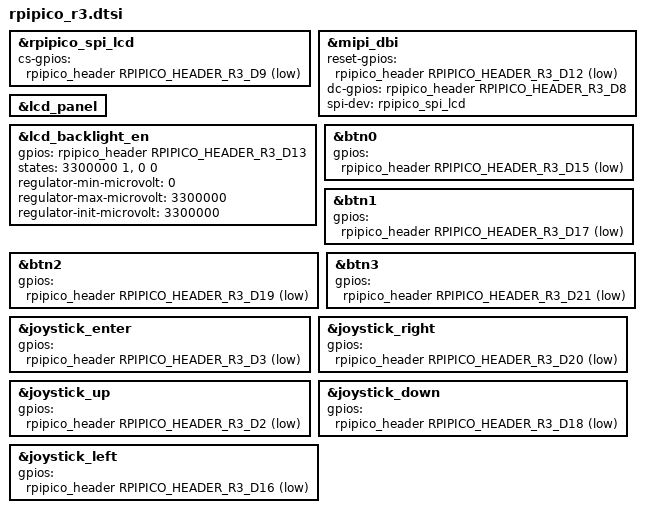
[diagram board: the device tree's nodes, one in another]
/*
 * SPDX-FileCopyrightText: Copyright (c) 2024-2026 TiaC Systems
 * SPDX-License-Identifier: Apache-2.0
 */

#include "rpipico_r3-connect.dtsi"

#include "st7789v_240x240ls.dtsi"

#include <zephyr/dt-bindings/gpio/gpio.h>

#include <zephyr/dt-bindings/gpio/raspberrypi-pico-header-r3.h>

&rpipico_spi_lcd {
	status = "okay";
	cs-gpios = <&rpipico_header RPIPICO_HEADER_R3_D9 GPIO_ACTIVE_LOW>;	/* GP9 */
};

&mipi_dbi {
	status = "okay";
	reset-gpios = <&rpipico_header RPIPICO_HEADER_R3_D12 GPIO_ACTIVE_LOW>;	/* GP12 */
	dc-gpios = <&rpipico_header RPIPICO_HEADER_R3_D8 GPIO_ACTIVE_HIGH>;	/* GP8 */
	spi-dev = <&rpipico_spi_lcd>;
	#address-cells = <1>;
	#size-cells = <0>;
};

&lcd_panel {
	status = "okay";
};

&lcd_backlight_en {
	status = "okay";
	gpios = <&rpipico_header RPIPICO_HEADER_R3_D13 GPIO_ACTIVE_HIGH>;	/* GP13 */
	states = <3300000 1>, <0 0>;
	regulator-min-microvolt = <0>;
	regulator-max-microvolt = <3300000>;
	regulator-init-microvolt = <3300000>;
};

&btn0 {										/* GP15 */
	gpios = <&rpipico_header RPIPICO_HEADER_R3_D15 (GPIO_PULL_UP | GPIO_ACTIVE_LOW)>;
};

&btn1 {										/* GP17 */
	gpios = <&rpipico_header RPIPICO_HEADER_R3_D17 (GPIO_PULL_UP | GPIO_ACTIVE_LOW)>;
};

&btn2 {										/* GP19 */
	gpios = <&rpipico_header RPIPICO_HEADER_R3_D19 (GPIO_PULL_UP | GPIO_ACTIVE_LOW)>;
};

&btn3 {										/* GP21 */
	gpios = <&rpipico_header RPIPICO_HEADER_R3_D21 (GPIO_PULL_UP | GPIO_ACTIVE_LOW)>;
};

&joystick_enter {								/* GP3 */
	gpios = <&rpipico_header RPIPICO_HEADER_R3_D3 (GPIO_PULL_UP | GPIO_ACTIVE_LOW)>;
};

&joystick_right {								/* GP20 */
	gpios = <&rpipico_header RPIPICO_HEADER_R3_D20 (GPIO_PULL_UP | GPIO_ACTIVE_LOW)>;
};

&joystick_up {									/* GP2 */
	gpios = <&rpipico_header RPIPICO_HEADER_R3_D2 (GPIO_PULL_UP | GPIO_ACTIVE_LOW)>;
};

&joystick_down {								/* GP18 */
	gpios = <&rpipico_header RPIPICO_HEADER_R3_D18 (GPIO_PULL_UP | GPIO_ACTIVE_LOW)>;
};

&joystick_left {								/* GP16 */
	gpios = <&rpipico_header RPIPICO_HEADER_R3_D16 (GPIO_PULL_UP | GPIO_ACTIVE_LOW)>;
};
